AUTOSAR XML (schema 00046)
package /ComponentTypes
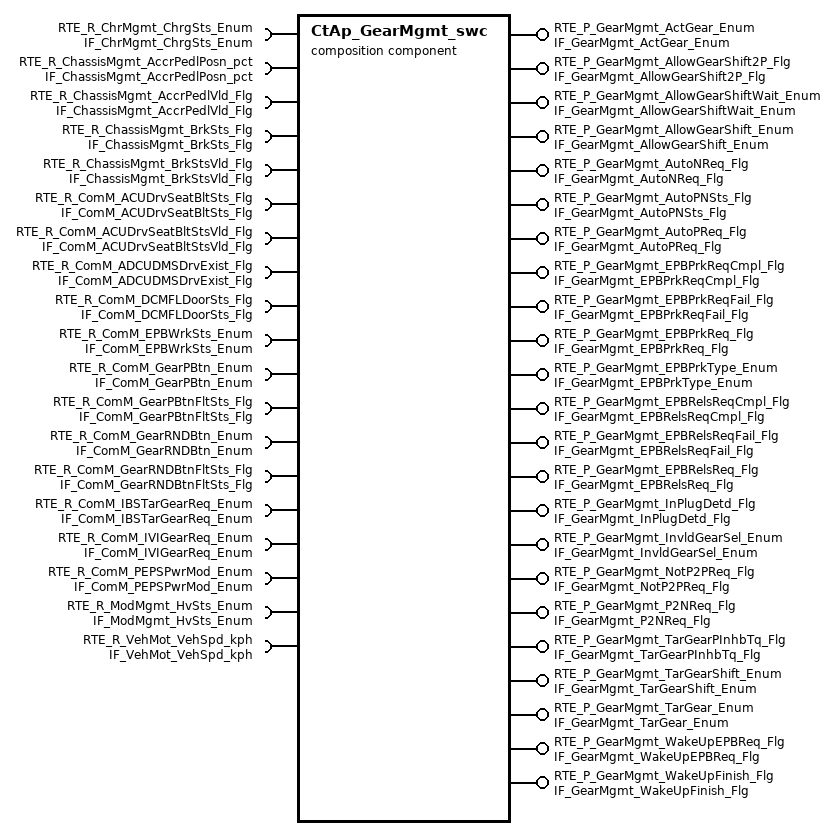
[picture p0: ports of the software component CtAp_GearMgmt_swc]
  composition sw component type CtAp_GearMgmt_swc
    23 x provide port:
      RTE_P_GearMgmt_ActGear_Enum: nonqueued-sender-com-spec{data-element=tec_GearMgmt_ActGear_Enum, init-value=0}, provided-interface=IF_GearMgmt_ActGear_Enum
      RTE_P_GearMgmt_AllowGearShift2P_Flg: nonqueued-sender-com-spec{data-element=tec_GearMgmt_AllowGearShift2P_Flg, init-value=0}, provided-interface=IF_GearMgmt_AllowGearShift2P_Flg
      RTE_P_GearMgmt_AllowGearShiftWait_Enum: nonqueued-sender-com-spec{data-element=tec_GearMgmt_AllowGearShiftWait_Enum, init-value=0}, provided-interface=IF_GearMgmt_AllowGearShiftWait_Enum
      RTE_P_GearMgmt_AllowGearShift_Enum: nonqueued-sender-com-spec{data-element=tec_GearMgmt_AllowGearShift_Enum, init-value=0}, provided-interface=IF_GearMgmt_AllowGearShift_Enum
      RTE_P_GearMgmt_AutoNReq_Flg: nonqueued-sender-com-spec{data-element=tec_GearMgmt_AutoNReq_Flg, init-value=0}, provided-interface=IF_GearMgmt_AutoNReq_Flg
      RTE_P_GearMgmt_AutoPNSts_Flg: nonqueued-sender-com-spec{data-element=tec_GearMgmt_AutoPNSts_Flg, init-value=0}, provided-interface=IF_GearMgmt_AutoPNSts_Flg
      RTE_P_GearMgmt_AutoPReq_Flg: nonqueued-sender-com-spec{data-element=tec_GearMgmt_AutoPReq_Flg, init-value=0}, provided-interface=IF_GearMgmt_AutoPReq_Flg
      RTE_P_GearMgmt_EPBPrkReqCmpl_Flg: nonqueued-sender-com-spec{data-element=tec_GearMgmt_EPBPrkReqCmpl_Flg, init-value=0}, provided-interface=IF_GearMgmt_EPBPrkReqCmpl_Flg
      RTE_P_GearMgmt_EPBPrkReqFail_Flg: nonqueued-sender-com-spec{data-element=tec_GearMgmt_EPBPrkReqFail_Flg, init-value=0}, provided-interface=IF_GearMgmt_EPBPrkReqFail_Flg
      RTE_P_GearMgmt_EPBPrkReq_Flg: nonqueued-sender-com-spec{data-element=tec_GearMgmt_EPBPrkReq_Flg, init-value=0}, provided-interface=IF_GearMgmt_EPBPrkReq_Flg
      RTE_P_GearMgmt_EPBPrkType_Enum: nonqueued-sender-com-spec{data-element=tec_GearMgmt_EPBPrkType_Enum, init-value=0}, provided-interface=IF_GearMgmt_EPBPrkType_Enum
      RTE_P_GearMgmt_EPBRelsReqCmpl_Flg: nonqueued-sender-com-spec{data-element=tec_GearMgmt_EPBRelsReqCmpl_Flg, init-value=0}, provided-interface=IF_GearMgmt_EPBRelsReqCmpl_Flg
      RTE_P_GearMgmt_EPBRelsReqFail_Flg: nonqueued-sender-com-spec{data-element=tec_GearMgmt_EPBRelsReqFail_Flg, init-value=0}, provided-interface=IF_GearMgmt_EPBRelsReqFail_Flg
      RTE_P_GearMgmt_EPBRelsReq_Flg: nonqueued-sender-com-spec{data-element=tec_GearMgmt_EPBRelsReq_Flg, init-value=0}, provided-interface=IF_GearMgmt_EPBRelsReq_Flg
      RTE_P_GearMgmt_InPlugDetd_Flg: nonqueued-sender-com-spec{data-element=tec_GearMgmt_InPlugDetd_Flg, init-value=0}, provided-interface=IF_GearMgmt_InPlugDetd_Flg
      RTE_P_GearMgmt_InvldGearSel_Enum: nonqueued-sender-com-spec{data-element=tec_GearMgmt_InvldGearSel_Enum, init-value=0}, provided-interface=IF_GearMgmt_InvldGearSel_Enum
      RTE_P_GearMgmt_NotP2PReq_Flg: nonqueued-sender-com-spec{data-element=tec_GearMgmt_NotP2PReq_Flg, init-value=0}, provided-interface=IF_GearMgmt_NotP2PReq_Flg
      RTE_P_GearMgmt_P2NReq_Flg: nonqueued-sender-com-spec{data-element=tec_GearMgmt_P2NReq_Flg, init-value=0}, provided-interface=IF_GearMgmt_P2NReq_Flg
      RTE_P_GearMgmt_TarGearPInhbTq_Flg: nonqueued-sender-com-spec{data-element=tec_GearMgmt_TarGearPInhbTq_Flg, init-value=0}, provided-interface=IF_GearMgmt_TarGearPInhbTq_Flg
      RTE_P_GearMgmt_TarGearShift_Enum: nonqueued-sender-com-spec{data-element=tec_GearMgmt_TarGearShift_Enum, init-value=0}, provided-interface=IF_GearMgmt_TarGearShift_Enum
      RTE_P_GearMgmt_TarGear_Enum: nonqueued-sender-com-spec{data-element=tec_GearMgmt_TarGear_Enum, init-value=0}, provided-interface=IF_GearMgmt_TarGear_Enum
      RTE_P_GearMgmt_WakeUpEPBReq_Flg: nonqueued-sender-com-spec{data-element=tec_GearMgmt_WakeUpEPBReq_Flg, init-value=0}, provided-interface=IF_GearMgmt_WakeUpEPBReq_Flg
      RTE_P_GearMgmt_WakeUpFinish_Flg: nonqueued-sender-com-spec{data-element=tec_GearMgmt_WakeUpFinish_Flg, init-value=0}, provided-interface=IF_GearMgmt_WakeUpFinish_Flg
    19 x require port:
      RTE_R_ChrMgmt_ChrgSts_Enum: nonqueued-receiver-com-spec{data-element=tec_ChrMgmt_ChrgSts_Enum, filter=data-filter-type=ALWAYS, init-value=0}, required-interface=IF_ChrMgmt_ChrgSts_Enum
      RTE_R_ChassisMgmt_AccrPedlPosn_pct: nonqueued-receiver-com-spec{data-element=tec_ChassisMgmt_AccrPedlPosn_pct, filter=data-filter-type=ALWAYS, init-value=0}, required-interface=IF_ChassisMgmt_AccrPedlPosn_pct
      RTE_R_ChassisMgmt_AccrPedlVld_Flg: nonqueued-receiver-com-spec{data-element=tec_ChassisMgmt_AccrPedlVld_Flg, filter=data-filter-type=ALWAYS, init-value=0}, required-interface=IF_ChassisMgmt_AccrPedlVld_Flg
      RTE_R_ChassisMgmt_BrkSts_Flg: nonqueued-receiver-com-spec{data-element=tec_ChassisMgmt_BrkSts_Flg, filter=data-filter-type=ALWAYS, init-value=0}, required-interface=IF_ChassisMgmt_BrkSts_Flg
      RTE_R_ChassisMgmt_BrkStsVld_Flg: nonqueued-receiver-com-spec{data-element=tec_ChassisMgmt_BrkStsVld_Flg, filter=data-filter-type=ALWAYS, init-value=0}, required-interface=IF_ChassisMgmt_BrkStsVld_Flg
      RTE_R_ComM_ACUDrvSeatBltSts_Flg: nonqueued-receiver-com-spec{data-element=tec_ComM_ACUDrvSeatBltSts_Flg, filter=data-filter-type=ALWAYS, init-value=0}, required-interface=IF_ComM_ACUDrvSeatBltSts_Flg
      RTE_R_ComM_ACUDrvSeatBltStsVld_Flg: nonqueued-receiver-com-spec{data-element=tec_ComM_ACUDrvSeatBltStsVld_Flg, filter=data-filter-type=ALWAYS, init-value=0}, required-interface=IF_ComM_ACUDrvSeatBltStsVld_Flg
      RTE_R_ComM_ADCUDMSDrvExist_Flg: nonqueued-receiver-com-spec{data-element=tec_ComM_ADCUDMSDrvrExist_Flg, filter=data-filter-type=ALWAYS, init-value=0}, required-interface=IF_ComM_ADCUDMSDrvExist_Flg
      RTE_R_ComM_DCMFLDoorSts_Flg: nonqueued-receiver-com-spec{data-element=tec_ComM_DCMFLDoorSts_Flg, filter=data-filter-type=ALWAYS, init-value=0}, required-interface=IF_ComM_DCMFLDoorSts_Flg
      RTE_R_ComM_EPBWrkSts_Enum: nonqueued-receiver-com-spec{data-element=tec_ComM_EPBWrkSts_Enum, filter=data-filter-type=ALWAYS, init-value=0}, required-interface=IF_ComM_EPBWrkSts_Enum
      RTE_R_ComM_GearPBtn_Enum: nonqueued-receiver-com-spec{data-element=tec_ComM_GearPBtn_Enum, filter=data-filter-type=ALWAYS, init-value=0}, required-interface=IF_ComM_GearPBtn_Enum
      RTE_R_ComM_GearPBtnFltSts_Flg: nonqueued-receiver-com-spec{data-element=tec_ComM_GearPBtnFltSts_Flg, filter=data-filter-type=ALWAYS, init-value=0}, required-interface=IF_ComM_GearPBtnFltSts_Flg
      RTE_R_ComM_GearRNDBtn_Enum: nonqueued-receiver-com-spec{data-element=tec_ComM_GearRNDBtn_Enum, filter=data-filter-type=ALWAYS, init-value=0}, required-interface=IF_ComM_GearRNDBtn_Enum
      RTE_R_ComM_GearRNDBtnFltSts_Flg: nonqueued-receiver-com-spec{data-element=tec_ComM_GearRNDBtnFltSts_Flg, filter=data-filter-type=ALWAYS, init-value=0}, required-interface=IF_ComM_GearRNDBtnFltSts_Flg
      RTE_R_ComM_IBSTarGearReq_Enum: nonqueued-receiver-com-spec{data-element=tec_ComM_IBSTarGearReq_Enum, filter=data-filter-type=ALWAYS, init-value=0}, required-interface=IF_ComM_IBSTarGearReq_Enum
      RTE_R_ComM_IVIGearReq_Enum: nonqueued-receiver-com-spec{data-element=tec_ComM_IVIGearReq_Enum, filter=data-filter-type=ALWAYS, init-value=0}, required-interface=IF_ComM_IVIGearReq_Enum
      RTE_R_ComM_PEPSPwrMod_Enum: nonqueued-receiver-com-spec{data-element=tec_ComM_PEPSPwrMod_Enum, filter=data-filter-type=ALWAYS, init-value=0}, required-interface=IF_ComM_PEPSPwrMod_Enum
      RTE_R_ModMgmt_HvSts_Enum: nonqueued-receiver-com-spec{data-element=tec_ModMgmt_HvSts_Enum, filter=data-filter-type=ALWAYS, init-value=0}, required-interface=IF_ModMgmt_HvSts_Enum
      RTE_R_VehMot_VehSpd_kph: nonqueued-receiver-com-spec{data-element=tec_VehMot_VehSpd_kph, filter=data-filter-type=ALWAYS, init-value=0}, required-interface=IF_VehMot_VehSpd_kph
    5 x component:
      CtAp_ManSftGear: type=CtAp_ManSftGear
      CtAp_AutoSftGear: type=CtAp_AutoSftGear
      CtAp_EPBLink: type=CtAp_EPBLink
      CtAp_GearCoor: type=CtAp_GearCoor
      CtAp_GearDiag: type=CtAp_GearDiag
    connect CtAp_AutoSftGear.RTE_P_GearMgmt_AutoNReq_Flg -> CtAp_GearCoor.RTE_R_GearMgmt_AutoNReq_Flg
    connect CtAp_AutoSftGear.RTE_P_GearMgmt_AutoPNSts_Flg -> CtAp_EPBLink.RTE_R_GearMgmt_AutoPNSts_Flg
    connect CtAp_ManSftGear.RTE_P_GearMgmt_TarGearShift_Enum -> CtAp_GearDiag.RTE_R_GearMgmt_TarGearShift_Enum
    delegate CtAp_GearCoor.RTE_P_GearMgmt_ActGear_Enum <-> outer port RTE_P_GearMgmt_ActGear_Enum
    delegate CtAp_EPBLink.RTE_P_GearMgmt_AllowGearShift2P_Flg <-> outer port RTE_P_GearMgmt_AllowGearShift2P_Flg
    delegate CtAp_ManSftGear.RTE_P_GearMgmt_AllowGearShift_Enum <-> outer port RTE_P_GearMgmt_AllowGearShift_Enum
    delegate CtAp_ManSftGear.RTE_P_GearMgmt_AllowGearShiftWait_Enum <-> outer port RTE_P_GearMgmt_AllowGearShiftWait_Enum
    delegate CtAp_AutoSftGear.RTE_P_GearMgmt_AutoNReq_Flg <-> outer port RTE_P_GearMgmt_AutoNReq_Flg
    delegate CtAp_AutoSftGear.RTE_P_GearMgmt_AutoPNSts_Flg <-> outer port RTE_P_GearMgmt_AutoPNSts_Flg
    delegate CtAp_AutoSftGear.RTE_P_GearMgmt_AutoPReq_Flg <-> outer port RTE_P_GearMgmt_AutoPReq_Flg
    delegate CtAp_EPBLink.RTE_P_GearMgmt_EPBPrkReq_Flg <-> outer port RTE_P_GearMgmt_EPBPrkReq_Flg
    delegate CtAp_EPBLink.RTE_P_GearMgmt_EPBPrkReqCmpl_Flg <-> outer port RTE_P_GearMgmt_EPBPrkReqCmpl_Flg
    delegate CtAp_EPBLink.RTE_P_GearMgmt_EPBPrkReqFail_Flg <-> outer port RTE_P_GearMgmt_EPBPrkReqFail_Flg
    delegate CtAp_EPBLink.RTE_P_GearMgmt_EPBPrkType_Enum <-> outer port RTE_P_GearMgmt_EPBPrkType_Enum
    delegate CtAp_EPBLink.RTE_P_GearMgmt_EPBRelsReq_Flg <-> outer port RTE_P_GearMgmt_EPBRelsReq_Flg
    delegate CtAp_EPBLink.RTE_P_GearMgmt_EPBRelsReqCmpl_Flg <-> outer port RTE_P_GearMgmt_EPBRelsReqCmpl_Flg
    delegate CtAp_EPBLink.RTE_P_GearMgmt_EPBRelsReqFail_Flg <-> outer port RTE_P_GearMgmt_EPBRelsReqFail_Flg
    delegate CtAp_ManSftGear.RTE_P_GearMgmt_InPlugDetd_Flg <-> outer port RTE_P_GearMgmt_InPlugDetd_Flg
    delegate CtAp_GearDiag.RTE_P_GearMgmt_InvldGearSel_Enum <-> outer port RTE_P_GearMgmt_InvldGearSel_Enum
    delegate CtAp_AutoSftGear.RTE_P_GearMgmt_NotP2PReq_Flg <-> outer port RTE_P_GearMgmt_NotP2PReq_Flg
    delegate CtAp_AutoSftGear.RTE_P_GearMgmt_P2NReq_Flg <-> outer port RTE_P_GearMgmt_P2NReq_Flg
    delegate CtAp_ManSftGear.RTE_P_GearMgmt_TarGear_Enum <-> outer port RTE_P_GearMgmt_TarGear_Enum
    delegate CtAp_GearCoor.RTE_P_GearMgmt_TarGearPInhbTq_Flg <-> outer port RTE_P_GearMgmt_TarGearPInhbTq_Flg
    delegate CtAp_ManSftGear.RTE_P_GearMgmt_TarGearShift_Enum <-> outer port RTE_P_GearMgmt_TarGearShift_Enum
    delegate CtAp_GearCoor.RTE_P_GearMgmt_WakeUpFinish_Flg <-> outer port RTE_P_GearMgmt_WakeUpFinish_Flg
    connect CtAp_GearCoor.RTE_P_GearMgmt_ActGear_Enum -> CtAp_AutoSftGear.RTE_R_GearMgmt_ActGear_Enum
    connect CtAp_ManSftGear.RTE_P_GearMgmt_InPlugDetd_Flg -> CtAp_AutoSftGear.RTE_R_GearMgmt_InPlugDetd_Flg
    connect CtAp_AutoSftGear.RTE_P_GearMgmt_AutoPReq_Flg -> CtAp_EPBLink.RTE_R_GearMgmt_AutoPReq_Flg
    connect CtAp_AutoSftGear.RTE_P_GearMgmt_NotP2PReq_Flg -> CtAp_EPBLink.RTE_R_GearMgmt_NotP2PReq_Flg
    connect CtAp_EPBLink.RTE_P_GearMgmt_AllowGearShift2P_Flg -> CtAp_GearCoor.RTE_R_GearMgmt_AllowGearShift2P_Flg
    connect CtAp_ManSftGear.RTE_P_GearMgmt_AllowGearShift_Enum -> CtAp_GearCoor.RTE_R_GearMgmt_AllowGearShift_Enum
    connect CtAp_AutoSftGear.RTE_P_GearMgmt_P2NReq_Flg -> CtAp_GearCoor.RTE_R_GearMgmt_P2NReq_Flg
    connect CtAp_AutoSftGear.RTE_P_GearMgmt_AutoPReq_Flg -> CtAp_GearDiag.RTE_R_GearMgmt_AutoPReq_Flg
    connect CtAp_EPBLink.RTE_P_GearMgmt_EPBPrkReqFail_Flg -> CtAp_GearDiag.RTE_R_GearMgmt_EPBPrkReqFail_Flg
    connect CtAp_EPBLink.RTE_P_GearMgmt_EPBPrkType_Enum -> CtAp_GearDiag.RTE_R_GearMgmt_EPBPrkType_Enum
    connect CtAp_EPBLink.RTE_P_GearMgmt_EPBRelsReqFail_Flg -> CtAp_GearDiag.RTE_R_GearMgmt_EPBRelsReqFail_Flg
    connect CtAp_ManSftGear.RTE_P_GearMgmt_InPlugDetd_Flg -> CtAp_GearDiag.RTE_R_GearMgmt_InPlugDetd_Flg
    connect CtAp_GearCoor.RTE_P_GearMgmt_ActGear_Enum -> CtAp_ManSftGear.RTE_R_GearMgmt_ActGear_Enum
    connect CtAp_EPBLink.RTE_P_GearMgmt_EPBPrkReqCmpl_Flg -> CtAp_ManSftGear.RTE_R_GearMgmt_EPBPrkReqCmpl_Flg
    connect CtAp_EPBLink.RTE_P_GearMgmt_EPBRelsReqCmpl_Flg -> CtAp_ManSftGear.RTE_R_GearMgmt_EPBRelsReqCmpl_Flg
    connect CtAp_GearCoor.RTE_P_GearMgmt_WakeUpFinish_Flg -> CtAp_ManSftGear.RTE_R_GearMgmt_WakeUpFinish_Flg
    delegate CtAp_GearCoor.RTE_P_GearMgmt_WakeUpEPBReq_Flg <-> outer port RTE_P_GearMgmt_WakeUpEPBReq_Flg
    delegate CtAp_AutoSftGear.RTE_R_ComM_ACUDrvSeatBltSts_Flg <-> outer port RTE_R_ComM_ACUDrvSeatBltSts_Flg
    delegate CtAp_AutoSftGear.RTE_R_ComM_ACUDrvSeatBltStsVld_Flg <-> outer port RTE_R_ComM_ACUDrvSeatBltStsVld_Flg
    delegate CtAp_AutoSftGear.RTE_R_ComM_ADCUDMSDrvExist_Flg <-> outer port RTE_R_ComM_ADCUDMSDrvExist_Flg
    delegate CtAp_AutoSftGear.RTE_R_ComM_DCMFLDoorSts_Flg <-> outer port RTE_R_ComM_DCMFLDoorSts_Flg
    delegate CtAp_AutoSftGear.RTE_R_ComM_EPBWrkSts_Enum <-> outer port RTE_R_ComM_EPBWrkSts_Enum
    delegate CtAp_AutoSftGear.RTE_R_ComM_PEPSPwrMod_Enum <-> outer port RTE_R_ComM_PEPSPwrMod_Enum
    delegate CtAp_AutoSftGear.RTE_R_ModMgmt_HvSts_Enum <-> outer port RTE_R_ModMgmt_HvSts_Enum
    delegate CtAp_AutoSftGear.RTE_R_VehMot_VehSpd_kph <-> outer port RTE_R_VehMot_VehSpd_kph
    delegate CtAp_EPBLink.RTE_R_ComM_EPBWrkSts_Enum <-> outer port RTE_R_ComM_EPBWrkSts_Enum
    connect CtAp_ManSftGear.RTE_P_GearMgmt_AllowGearShiftWait_Enum -> CtAp_EPBLink.RTE_R_GearMgmt_AllowGearShiftWait_Enum
    connect CtAp_GearCoor.RTE_P_GearMgmt_WakeUpEPBReq_Flg -> CtAp_EPBLink.RTE_R_GearMgmt_WakeUpEPBReq_Flg
    delegate CtAp_GearCoor.RTE_R_ComM_EPBWrkSts_Enum <-> outer port RTE_R_ComM_EPBWrkSts_Enum
    delegate CtAp_GearCoor.RTE_R_VehMot_VehSpd_kph <-> outer port RTE_R_VehMot_VehSpd_kph
    delegate CtAp_GearDiag.RTE_R_ChassisMgmt_AccrPedlPosn_pct <-> outer port RTE_R_ChassisMgmt_AccrPedlPosn_pct
    delegate CtAp_GearDiag.RTE_R_ChassisMgmt_AccrPedlVld_Flg <-> outer port RTE_R_ChassisMgmt_AccrPedlVld_Flg
    delegate CtAp_GearDiag.RTE_R_ChassisMgmt_BrkSts_Flg <-> outer port RTE_R_ChassisMgmt_BrkSts_Flg
    delegate CtAp_GearDiag.RTE_R_ChassisMgmt_BrkStsVld_Flg <-> outer port RTE_R_ChassisMgmt_BrkStsVld_Flg
    delegate CtAp_GearDiag.RTE_R_ComM_EPBWrkSts_Enum <-> outer port RTE_R_ComM_EPBWrkSts_Enum
    delegate CtAp_GearDiag.RTE_R_ComM_GearPBtnFltSts_Flg <-> outer port RTE_R_ComM_GearPBtnFltSts_Flg
    delegate CtAp_GearDiag.RTE_R_ComM_GearRNDBtnFltSts_Flg <-> outer port RTE_R_ComM_GearRNDBtnFltSts_Flg
    delegate CtAp_GearDiag.RTE_R_ModMgmt_HvSts_Enum <-> outer port RTE_R_ModMgmt_HvSts_Enum
    delegate CtAp_GearDiag.RTE_R_VehMot_VehSpd_kph <-> outer port RTE_R_VehMot_VehSpd_kph
    delegate CtAp_ManSftGear.RTE_R_ChassisMgmt_AccrPedlPosn_pct <-> outer port RTE_R_ChassisMgmt_AccrPedlPosn_pct
    delegate CtAp_ManSftGear.RTE_R_ChassisMgmt_AccrPedlVld_Flg <-> outer port RTE_R_ChassisMgmt_AccrPedlVld_Flg
    delegate CtAp_ManSftGear.RTE_R_ChassisMgmt_BrkSts_Flg <-> outer port RTE_R_ChassisMgmt_BrkSts_Flg
    delegate CtAp_ManSftGear.RTE_R_ChassisMgmt_BrkStsVld_Flg <-> outer port RTE_R_ChassisMgmt_BrkStsVld_Flg
    delegate CtAp_ManSftGear.RTE_R_ChrMgmt_ChrgSts_Enum <-> outer port RTE_R_ChrMgmt_ChrgSts_Enum
    delegate CtAp_ManSftGear.RTE_R_ComM_GearPBtn_Enum <-> outer port RTE_R_ComM_GearPBtn_Enum
    delegate CtAp_ManSftGear.RTE_R_ComM_GearPBtnFltSts_Flg <-> outer port RTE_R_ComM_GearPBtnFltSts_Flg
    delegate CtAp_ManSftGear.RTE_R_ComM_GearRNDBtn_Enum <-> outer port RTE_R_ComM_GearRNDBtn_Enum
    delegate CtAp_ManSftGear.RTE_R_ComM_GearRNDBtnFltSts_Flg <-> outer port RTE_R_ComM_GearRNDBtnFltSts_Flg
    delegate CtAp_ManSftGear.RTE_R_ComM_IBSTarGearReq_Enum <-> outer port RTE_R_ComM_IBSTarGearReq_Enum
    delegate CtAp_ManSftGear.RTE_R_ComM_IVIGearReq_Enum <-> outer port RTE_R_ComM_IVIGearReq_Enum
    delegate CtAp_ManSftGear.RTE_R_ModMgmt_HvSts_Enum <-> outer port RTE_R_ModMgmt_HvSts_Enum
    delegate CtAp_ManSftGear.RTE_R_VehMot_VehSpd_kph <-> outer port RTE_R_VehMot_VehSpd_kph
